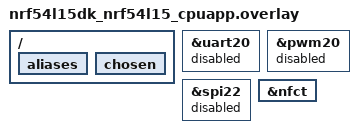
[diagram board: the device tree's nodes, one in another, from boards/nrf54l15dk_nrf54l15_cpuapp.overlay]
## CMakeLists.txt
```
#
# Copyright (c) 2018 Nordic Semiconductor
#
# SPDX-License-Identifier: LicenseRef-Nordic-5-Clause
#

cmake_minimum_required(VERSION 3.20.0)

find_package(Zephyr REQUIRED HINTS $ENV{ZEPHYR_BASE})
project(writable_ndef_msg)

FILE(GLOB app_sources src/*.c)

# NORDIC SDK APP START
target_sources(app  PRIVATE ${app_sources})
# NORDIC SDK APP END
```

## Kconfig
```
#
# Copyright (c) 2025 Nordic Semiconductor
#
# SPDX-License-Identifier: LicenseRef-Nordic-5-Clause
#

source "Kconfig.zephyr"

config ZMS
	select CRC
	default y if (SOC_FLASH_NRF_RRAM || SOC_FLASH_NRF_MRAM)

config NVS
	default y if !(SOC_FLASH_NRF_RRAM || SOC_FLASH_NRF_MRAM)

menu "Nordic UART BLE GATT service sample"

config BT_NUS_THREAD_STACK_SIZE
	int "Thread stack size"
	default 1024
	help
	  Stack size used for the BLE write thread

config BT_NUS_UART_BUFFER_SIZE
	int "UART payload buffer element size"
	default 40
	help
	  Size of the payload buffer in each RX and TX FIFO element

config BT_NUS_SECURITY_ENABLED
	bool "Security"
	default y
	select BT_SMP
	help
	  Enable Bluetooth LE security for the UART service

config BT_NUS_UART_RX_WAIT_TIME
	int "Timeout for UART RX complete event"
	default 50000
	help
	  Wait for RX complete event time in microseconds

config SETTINGS
	default y

endmenu
```

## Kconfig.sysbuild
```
#
# Copyright (c) 2025 Nordic Semiconductor ASA
#
# SPDX-License-Identifier: LicenseRef-Nordic-5-Clause
#

config PARTITION_MANAGER
	default n if !BOARD_IS_NON_SECURE

config NRF_DEFAULT_IPC_RADIO
	default y

config NETCORE_IPC_RADIO_BT_HCI_IPC
	default y

source "share/sysbuild/Kconfig"
```

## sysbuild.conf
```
#
# Copyright (c) 2026 Nordic Semiconductor
#
# SPDX-License-Identifier: LicenseRef-Nordic-5-Clause
#

# BLE requires the network core on multi-core SoCs (nRF5340, nRF54H20).
# For single-core SoCs (nRF52840, nRF52) this has no effect.
```

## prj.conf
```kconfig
#
# Copyright (c) 2019 Nordic Semiconductor ASA
#
# SPDX-License-Identifier: LicenseRef-Nordic-5-Clause
#
CONFIG_NCS_SAMPLES_DEFAULTS=y

# NFC
CONFIG_NFC_T4T_NRFXLIB=y

CONFIG_NFC_NDEF=y
CONFIG_NFC_NDEF_MSG=y
CONFIG_NFC_NDEF_RECORD=y
CONFIG_NFC_NDEF_URI_REC=y
CONFIG_NFC_NDEF_URI_MSG=y

CONFIG_MPU_ALLOW_FLASH_WRITE=y
CONFIG_FLASH=y
CONFIG_FLASH_PAGE_LAYOUT=y
CONFIG_FLASH_MAP=y

# DK buttons and LEDs
CONFIG_DK_LIBRARY=y

CONFIG_SERIAL=y

CONFIG_GPIO=y
CONFIG_CONSOLE=y
CONFIG_UART_CONSOLE=y

# Shell CLI
CONFIG_SHELL=y
CONFIG_SHELL_BACKEND_SERIAL=y
CONFIG_SHELL_STACK_SIZE=2048

CONFIG_HEAP_MEM_POOL_SIZE=2048

# Bluetooth
CONFIG_BT=y
CONFIG_BT_PERIPHERAL=y
CONFIG_BT_DEVICE_NAME="RL_TN100"
CONFIG_BT_MAX_CONN=1
CONFIG_BT_MAX_PAIRED=1

# BT buffer pool — OTA 每包 492 字节，ATT payload 495，MTU 498
CONFIG_BT_L2CAP_TX_MTU=498
CONFIG_BT_BUF_ACL_TX_SIZE=502
CONFIG_BT_BUF_ACL_TX_COUNT=6
CONFIG_BT_BUF_ACL_RX_SIZE=502
CONFIG_BT_BUF_ACL_RX_COUNT_EXTRA=4
CONFIG_BT_BUF_EVT_RX_COUNT=12

# NUS service
CONFIG_BT_NUS=y

# Bonding
CONFIG_BT_SETTINGS=y

CONFIG_SYSTEM_WORKQUEUE_STACK_SIZE=2048

# Logger
CONFIG_LOG=y
CONFIG_LOG_MODE_MINIMAL=n
CONFIG_USE_SEGGER_RTT=n
CONFIG_LOG_BACKEND_RTT=n
CONFIG_LOG_BACKEND_UART=y
CONFIG_LOG_PRINTK=y

# Entropy for random nonce
CONFIG_ENTROPY_GENERATOR=y

CONFIG_ASSERT=y
```

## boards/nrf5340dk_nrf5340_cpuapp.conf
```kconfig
#
# Copyright (c) 2024 Nordic Semiconductor ASA
#
# SPDX-License-Identifier: LicenseRef-Nordic-5-Clause
#

# nRF5340 app core: use host crypto PRNG instead of
# getting entropy from the network core via HCI.
CONFIG_BT_HOST_CRYPTO_PRNG=y
CONFIG_ENTROPY_BT_HCI=n
```

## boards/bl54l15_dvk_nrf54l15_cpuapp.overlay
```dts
/*
 * DK/App integration overlay.
 *
 * Keep the nRF54L15 DK defaults for UART console, shell, LEDs and buttons,
 * and only enable the NFCT peripheral required by the writable NDEF sample.
 * The PCB-A pin-protection overlay belongs on the dedicated test branch.
 */

&nfct {
	status = "okay";
};
```

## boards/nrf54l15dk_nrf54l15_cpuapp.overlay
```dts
/*
 * Copyright (c) 2024-2026
 *
 * SPDX-License-Identifier: LicenseRef-Nordic-5-Clause
 *
 * PCB-A nRF54L15 最小 overlay — NFC + BLE 联调阶段
 *
 * 仅启用 NFC 和 BLE 两个可调试功能。
 * 其余外设引脚已按 docs/pcb_a_io_map.md 分配，
 * 待各外设驱动就绪后逐步加入此 overlay。
 */

/* ── 清除 DK 默认节点与别名（释放 GPIO） ── */
/ {
	/delete-node/ leds;
	/delete-node/ buttons;
	/delete-node/ pwmleds;

	aliases {
		/delete-property/ led0;
		/delete-property/ led1;
		/delete-property/ led2;
		/delete-property/ led3;
		/delete-property/ pwm-led0;
		/delete-property/ sw0;
		/delete-property/ sw1;
		/delete-property/ sw2;
		/delete-property/ sw3;
		/delete-property/ mcuboot-button0;
		/delete-property/ mcuboot-led0;
	};

	/* 清理 chosen 中引用已禁用 uart20 的属性，避免构建警告 */
	chosen {
		/delete-property/ zephyr,console;
		/delete-property/ zephyr,shell-uart;
		/delete-property/ zephyr,uart-mcumgr;
		/delete-property/ zephyr,bt-mon-uart;
		/delete-property/ zephyr,bt-c2h-uart;
	};
};

/* ── 释放 uart20 占用的 P1.04~P1.07 ── */
/* PCB-A: P1.04=NTC_ADC, P1.05=VBAT_ADC, P1.06=US_RX, P1.07=US_TX */
&uart20 {
	/delete-property/ pinctrl-0;
	/delete-property/ pinctrl-1;
	/delete-property/ pinctrl-names;
	status = "disabled";
};

/* ── 释放 pwm20 占用的 P1.10 ── */
/* PCB-A: P1.10=CC_I2C_SDA (ATECC608C) */
&pwm20 {
	/delete-property/ pinctrl-0;
	/delete-property/ pinctrl-1;
	/delete-property/ pinctrl-names;
	status = "disabled";
};

/* ── 释放 spi22 占用的 P1.06/P1.07/P1.11 ── */
/* PCB-A: P1.06=US_RX, P1.07=US_TX, P1.11=CC_I2C_SCL */
&spi22 {
	/delete-property/ pinctrl-0;
	/delete-property/ pinctrl-1;
	/delete-property/ pinctrl-names;
	/delete-property/ cs-gpios;
	status = "disabled";
};

/* ── GRTC — 无需禁用 ──
 * DK 默认 &grtc pinctrl (grtc_default/grtc_sleep) 使用 /omit-if-no-ref/ 编译指令，
 * 且 &grtc 节点本身未引用这两个 pinctrl 配置（见 rf54l_05_10_15_cpuapp_common.dtsi:53-58）。
 * 因此 GRTC CLKOUT_FAST(P1.08) / CLKOUT_32K(P0.04) 引脚不会被占用，
 * PCB-A 的 LED_PWM(P1.08) / ACC_I2C_SCL(P0.04) 无冲突风险。
 * GRTC 作为内部定时器保持使能，不影响 GPIO。
 */

/* ── NFC 使能（P1.02/P1.03 固定功能，与 PCB-A 一致） ── */
&nfct {
	status = "okay";
};

/* ── Flash SPIM00 — DK 默认与 PCB-A 一致，无需覆盖 ── */
/* P2.01=SCK, P2.02=MOSI, P2.04=MISO, P2.05=CS → W25Q32JVSSIQ */

/* ═══════════════════════════════════════════════════════════════
 * 以下为 PCB-A 外设预留引脚说明（暂不启用，只做文档记录）
 * 参见 docs/pcb_a_io_map.md 完整分配表
 * ═══════════════════════════════════════════════════════════════
 *
 * ── 硬件 I2C ──
 * TWIM30 (BMA510) : P0.04 SCL / P0.03 SDA  (常开低功耗域)
 * TWIM20 (TOF)    : P1.12 SCL / P1.13 SDA
 * TWIM22 (ATECC)  : P1.11 SCL / P1.10 SDA
 *
 * ── 硬件 UART ──
 * UART21 (LPWA)   : P2.08 TXD / P2.07 RXD  (P2.07 与 SWO 复用)
 *
 * ── 软件 UART (GPIO bit-bang) ──
 * 超声波           : P1.07 TX / P1.06 RX
 * GNSS (预留)      : P2.09 TX / P2.10 RX     (P2 无 GPIOTE)
 *
 * ── ADC ──
 * SAADC AIN0 (NTC) : P1.04
 * SAADC AIN1 (VBAT): P1.05
 *
 * ── GPIO ──
 * P0.00 NTC_INT    (输入, wake)
 * P0.01 REST_KEY   (输入, wake, 低有效)
 * P0.02 ACC_INT    (输入, wake, BMA510)
 * P1.08 LED_PWM    (输出, WS2812B)
 * P1.09 MK_EN      (输出, 电源控制, 默认关断)
 * P1.14 TOF_INT    (输入, wake)
 * P2.00 LPWA_POWER (输出, PWRKEY 时序)
 * P2.03 LPWA_EN    (输出, 电源使能)
 * P2.06 LPWA_PSM   (输出, PSM 控制)
 *
 * ── 固定功能（无需 overlay） ──
 * P1.00 OSC32IN / P1.01 OSC32OUT (32.768kHz 晶振)
 * P1.02 NFC1  / P1.03 NFC2       (NFC 天线)
 * ANT (BLE 射频)
 */
```

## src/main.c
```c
/*
 * Copyright (c) 2018 Nordic Semiconductor ASA
 *
 * SPDX-License-Identifier: LicenseRef-Nordic-5-Clause
 */

/** @file
 *
 * @defgroup nfc_writable_ndef_msg_example_main main.c
 * @{
 * @ingroup nfc_writable_ndef_msg_example
 * @brief The application main file of NFC writable NDEF message example.
 *
 */

#include <zephyr/kernel.h>
#include <zephyr/sys/reboot.h>
#include <stdbool.h>
#include <nfc_t4t_lib.h>

#include <nfc/ndef/msg.h>
#include <nfc/t4t/ndef_file.h>

#if defined(CONFIG_DK_LIBRARY)
#include <dk_buttons_and_leds.h>
#endif

#include "ndef_file_m.h"
#include "app_config.h"
#include "app_fields.h"
#include "app_auth.h"
#include "ble_uart.h"


#if defined(CONFIG_DK_LIBRARY)
#define NFC_FIELD_LED		DK_LED1
#define NFC_WRITE_LED		DK_LED2
#define NFC_READ_LED		DK_LED4

#define NDEF_RESTORE_BTN_MSK	DK_BTN1_MSK
#endif

static uint8_t ndef_msg_buf[CONFIG_NDEF_FILE_SIZE]; /**< Buffer for NDEF file. */

enum {
	FLASH_WRITE_FINISHED,
	FLASH_BUF_PREP_STARTED,
	FLASH_BUF_PREP_FINISHED,
	FLASH_WRITE_STARTED,
};
static atomic_t op_flags;
static uint8_t flash_buf[CONFIG_NDEF_FILE_SIZE]; /**< Buffer for flash update. */
static uint8_t flash_buf_len; /**< Length of the flash buffer. */

static K_SEM_DEFINE(nfc_write_sem, 0, 1);

static void flash_buffer_prepare(size_t data_length)
{
	if (atomic_cas(&op_flags, FLASH_WRITE_FINISHED,
			FLASH_BUF_PREP_STARTED)) {
		flash_buf_len = data_length + NFC_NDEF_FILE_NLEN_FIELD_SIZE;
		memcpy(flash_buf, ndef_msg_buf, sizeof(flash_buf));

		atomic_set(&op_flags, FLASH_BUF_PREP_FINISHED);
		k_sem_give(&nfc_write_sem);
	} else {
		printk("Flash update pending. Discarding new data...\n");
	}

}

/**
 * @brief Callback function for handling NFC events.
 */
static void nfc_callback(void *context,
			 nfc_t4t_event_t event,
			 const uint8_t *data,
			 size_t data_length,
			 uint32_t flags)
{
	ARG_UNUSED(context);
	ARG_UNUSED(flags);

	switch (event) {
	case NFC_T4T_EVENT_FIELD_ON:
#if defined(CONFIG_DK_LIBRARY)
		dk_set_led_on(NFC_FIELD_LED);
#endif
		break;

	case NFC_T4T_EVENT_FIELD_OFF:
#if defined(CONFIG_DK_LIBRARY)
		dk_set_led_off(NFC_FIELD_LED);
		dk_set_led_off(NFC_WRITE_LED);
		dk_set_led_off(NFC_READ_LED);
#endif
		break;

	case NFC_T4T_EVENT_NDEF_READ:
#if defined(CONFIG_DK_LIBRARY)
		dk_set_led_on(NFC_READ_LED);
#endif
		break;

	case NFC_T4T_EVENT_NDEF_UPDATED:
		if (data_length > 0) {
#if defined(CONFIG_DK_LIBRARY)
			dk_set_led_on(NFC_WRITE_LED);
#endif

			if (!app_config_handle_ndef(ndef_msg_buf, sizeof(ndef_msg_buf))) {
				flash_buffer_prepare(data_length);
			}
		}
		break;

	default:
		break;
	}
}

static int board_init(void)
{
#if defined(CONFIG_DK_LIBRARY)
	int err = dk_leds_init();
	if (err) {
		printk("Cannot init LEDs (err: %d)\n", err);
		return err;
	}
#endif

	return 0;
}

/**
 * @brief   Function for application main entry.
 */
int main(void)
{
	/* Configure LED-pins as outputs. */
	if (board_init() < 0) {
		printk("Cannot initialize board!\n");
		goto fail;
	}
	/* Initialize storage. */
	if (ndef_file_setup() < 0) {
		printk("Cannot setup NDEF file!\n");
		goto fail;
	}
	/* Load NDEF message from the flash file. */
	if (ndef_file_load(ndef_msg_buf, sizeof(ndef_msg_buf)) < 0) {
		printk("Cannot load NDEF file!\n");
		goto fail;
	}

#if defined(CONFIG_DK_LIBRARY)
	/* Restore default NDEF message if button is pressed. */
	uint32_t button_state;

	dk_read_buttons(&button_state, NULL);
	if (button_state & NDEF_RESTORE_BTN_MSK) {
		if (ndef_restore_default(ndef_msg_buf,
					 sizeof(ndef_msg_buf)) < 0) {
			printk("Cannot flash NDEF message!\n");
			goto fail;
		}
		printk("Default NDEF message restored!\n");
	}
#endif
	/* Set up NFC */
	int err = nfc_t4t_setup(nfc_callback, NULL);

	if (err < 0) {
		printk("Cannot setup t4t library!\n");
		goto fail;
	}
	/* Run Read-Write mode for Type 4 Tag platform */
	if (nfc_t4t_ndef_rwpayload_set(ndef_msg_buf,
				       sizeof(ndef_msg_buf)) < 0) {
		printk("Cannot set payload!\n");
		goto fail;
	}
	/* Start sensing NFC field */
	if (nfc_t4t_emulation_start() < 0) {
		printk("Cannot start emulation!\n");
		goto fail;
	}
	printk("Starting NFC Writable NDEF Message sample\n");

	/* Initialize authentication module */
	app_auth_init();
	/* Initialize field registry (V2.0 protocol) */
	app_fields_init();

	/* Initialize BLE UART service */
	err = ble_uart_init();
	if (err) {
		printk("Cannot initialize BLE UART (err: %d)\n", err);
		goto fail;
	}

	while (true) {
		k_sem_take(&nfc_write_sem, K_FOREVER);
		if (atomic_cas(&op_flags, FLASH_BUF_PREP_FINISHED,
				FLASH_WRITE_STARTED)) {
			if (ndef_file_update(flash_buf, flash_buf_len) < 0) {
				printk("Cannot flash NDEF message!\n");
			} else {
				printk("NDEF message successfully flashed.\n");
			}

			atomic_set(&op_flags, FLASH_WRITE_FINISHED);
		}
	}

fail:
	#if CONFIG_REBOOT
		sys_reboot(SYS_REBOOT_COLD);
	#endif /* CONFIG_REBOOT */
		return -EIO;
}
/** @} */
```

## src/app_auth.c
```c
/*
 * Copyright (c) 2024
 *
 * SPDX-License-Identifier: LicenseRef-Nordic-5-Clause
 */

/**
 * @file app_auth.c
 * @brief CMD 0x03 认证与密码管理模块。
 *
 * 测试阶段默认密码: 123456
 * password_hash = SHA256(password + device_sn + salt)
 * salt = "RL_RANGE_AUTH_V1"
 * token = HMAC_SHA256(password_hash, nonce + device_sn)
 *
 * SHA256 与 HMAC-SHA256 为自包含实现，不依赖外部密码库。
 *
 * 【密码持久化策略】
 * 本测试工程暂不将 password_hash 写入 Flash，修改密码仅保存在 RAM 中。
 * 设备重启后 password_hash 恢复为默认密码 "123456" 的计算值。
 * 如需完整测试修改密码，应使用 Zephyr settings 或 Flash KV 持久化
 * password_hash，在 app_auth_init() 中先从持久化存储加载，不存在时
 * 再 fallback 到默认密码。
 */

#include "app_auth.h"
#include "app_config.h"

#include <zephyr/kernel.h>
#include <zephyr/sys/printk.h>
#include <zephyr/random/random.h>

#include <string.h>

/* ── 设备身份 ── */

static const char g_sn[]   = "123456";      /* 与 app_config.c 保持一致 */
static const char g_salt[] = "RL_RANGE_AUTH_V1";

/* ── 默认测试密码 ── */

#define DEFAULT_PASSWORD "123456"

/* ── 密码哈希（32 字节 SHA256，设备端永不保留明文） ── */

static uint8_t g_password_hash[32];

/* ── BLE / NFC 独立 nonce 状态，避免两个通道互相覆盖 ── */

static uint8_t g_nonce_ble[8];
static bool    g_nonce_ble_valid;
static uint8_t g_nonce_nfc[8];
static bool    g_nonce_nfc_valid;

/* ── 按通道取 nonce 指针 ── */

static uint8_t *channel_nonce(const char *channel)
{
	return (channel[0] == 'B') ? g_nonce_ble : g_nonce_nfc;
}

static bool *channel_nonce_valid(const char *channel)
{
	return (channel[0] == 'B') ? &g_nonce_ble_valid : &g_nonce_nfc_valid;
}

/* ── 会话解锁状态 ── */

static bool     g_ble_unlocked;
static int64_t  g_nfc_auth_until_ms;  /* k_uptime_get() + 5*60*1000，0 = 锁定 */
#define NFC_AUTH_WINDOW_MS  (5 * 60 * 1000)

/* ═══════════════════════════════════════════════════════════════════════
 * 自包含 SHA256 实现 (FIPS 180-4)
 * ═══════════════════════════════════════════════════════════════════════ */

#define SHA256_BLOCK_SIZE 64
#define SHA256_HASH_SIZE  32

struct sha256_ctx {
	uint32_t state[8];
	uint64_t count;
	uint8_t  buf[SHA256_BLOCK_SIZE];
};

static const uint32_t sha256_k[64] = {
	0x428a2f98, 0x71374491, 0xb5c0fbcf, 0xe9b5dba5,
	0x3956c25b, 0x59f111f1, 0x923f82a4, 0xab1c5ed5,
	0xd807aa98, 0x12835b01, 0x243185be, 0x550c7dc3,
	0x72be5d74, 0x80deb1fe, 0x9bdc06a7, 0xc19bf174,
	0xe49b69c1, 0xefbe4786, 0x0fc19dc6, 0x240ca1cc,
	0x2de92c6f, 0x4a7484aa, 0x5cb0a9dc, 0x76f988da,
	0x983e5152, 0xa831c66d, 0xb00327c8, 0xbf597fc7,
	0xc6e00bf3, 0xd5a79147, 0x06ca6351, 0x14292967,
	0x27b70a85, 0x2e1b2138, 0x4d2c6dfc, 0x53380d13,
	0x650a7354, 0x766a0abb, 0x81c2c92e, 0x92722c85,
	0xa2bfe8a1, 0xa81a664b, 0xc24b8b70, 0xc76c51a3,
	0xd192e819, 0xd6990624, 0xf40e3585, 0x106aa070,
	0x19a4c116, 0x1e376c08, 0x2748774c, 0x34b0bcb5,
	0x391c0cb3, 0x4ed8aa4a, 0x5b9cca4f, 0x682e6ff3,
	0x748f82ee, 0x78a5636f, 0x84c87814, 0x8cc70208,
	0x90befffa, 0xa4506ceb, 0xbef9a3f7, 0xc67178f2
};

static inline uint32_t sha256_rotr(uint32_t x, uint32_t n)
{
	return (x >> n) | (x << (32 - n));
}

static inline uint32_t sha256_ch(uint32_t x, uint32_t y, uint32_t z)
{
	return (x & y) ^ (~x & z);
}

static inline uint32_t sha256_maj(uint32_t x, uint32_t y, uint32_t z)
{
	return (x & y) ^ (x & z) ^ (y & z);
}

static inline uint32_t sha256_bsig0(uint32_t x)
{
	return sha256_rotr(x, 2) ^ sha256_rotr(x, 13) ^ sha256_rotr(x, 22);
}

static inline uint32_t sha256_bsig1(uint32_t x)
{
	return sha256_rotr(x, 6) ^ sha256_rotr(x, 11) ^ sha256_rotr(x, 25);
}

static inline uint32_t sha256_ssig0(uint32_t x)
{
	return sha256_rotr(x, 7) ^ sha256_rotr(x, 18) ^ (x >> 3);
}

static inline uint32_t sha256_ssig1(uint32_t x)
{
	return sha256_rotr(x, 17) ^ sha256_rotr(x, 19) ^ (x >> 10);
}

static inline uint32_t sha256_get32be(const uint8_t *p)
{
	return ((uint32_t)p[0] << 24) | ((uint32_t)p[1] << 16) |
	       ((uint32_t)p[2] << 8)  |  (uint32_t)p[3];
}

static inline void sha256_put32be(uint8_t *p, uint32_t v)
{
	p[0] = (uint8_t)(v >> 24);
	p[1] = (uint8_t)(v >> 16);
	p[2] = (uint8_t)(v >> 8);
	p[3] = (uint8_t)(v);
}

static void sha256_transform(uint32_t *state, const uint8_t *block)
{
	uint32_t w[64];
	uint32_t a, b, c, d, e, f, g, h;
	uint32_t t1, t2;

	for (int i = 0; i < 16; i++) {
		w[i] = sha256_get32be(&block[i * 4]);
	}
	for (int i = 16; i < 64; i++) {
		w[i] = sha256_ssig1(w[i - 2]) + w[i - 7] +
		       sha256_ssig0(w[i - 15]) + w[i - 16];
	}

	a = state[0]; b = state[1]; c = state[2]; d = state[3];
	e = state[4]; f = state[5]; g = state[6]; h = state[7];

	for (int i = 0; i < 64; i++) {
		t1 = h + sha256_bsig1(e) + sha256_ch(e, f, g) + sha256_k[i] + w[i];
		t2 = sha256_bsig0(a) + sha256_maj(a, b, c);
		h = g; g = f; f = e; e = d + t1;
		d = c; c = b; b = a; a = t1 + t2;
	}

	state[0] += a; state[1] += b; state[2] += c; state[3] += d;
	state[4] += e; state[5] += f; state[6] += g; state[7] += h;
}

static void sha256_init(struct sha256_ctx *ctx)
{
	ctx->state[0] = 0x6a09e667;
	ctx->state[1] = 0xbb67ae85;
	ctx->state[2] = 0x3c6ef372;
	ctx->state[3] = 0xa54ff53a;
	ctx->state[4] = 0x510e527f;
	ctx->state[5] = 0x9b05688c;
	ctx->state[6] = 0x1f83d9ab;
	ctx->state[7] = 0x5be0cd19;
	ctx->count = 0;
}

static void sha256_update(struct sha256_ctx *ctx,
			  const uint8_t *data, size_t len)
{
	size_t idx = (size_t)(ctx->count & 0x3F); /* ctx->count % 64 */
	ctx->count += (uint64_t)len;

	while (len > 0) {
		size_t fill = SHA256_BLOCK_SIZE - idx;
		if (fill > len) {
			fill = len;
		}
		memcpy(ctx->buf + idx, data, fill);
		idx += fill;
		data += fill;
		len -= fill;

		if (idx == SHA256_BLOCK_SIZE) {
			sha256_transform(ctx->state, ctx->buf);
			idx = 0;
		}
	}
}

static void sha256_finish(struct sha256_ctx *ctx, uint8_t *hash)
{
	uint64_t bits = ctx->count * 8;
	size_t idx = (size_t)(ctx->count & 0x3F);

	/* padding: 0x80, then zeros, then 8-byte big-endian bit count */
	ctx->buf[idx++] = 0x80;
	if (idx > 56) {
		memset(ctx->buf + idx, 0, SHA256_BLOCK_SIZE - idx);
		sha256_transform(ctx->state, ctx->buf);
		idx = 0;
	}
	memset(ctx->buf + idx, 0, 56 - idx);
	sha256_put32be(ctx->buf + 56, (uint32_t)(bits >> 32));
	sha256_put32be(ctx->buf + 60, (uint32_t)(bits));
	sha256_transform(ctx->state, ctx->buf);

	for (int i = 0; i < 8; i++) {
		sha256_put32be(hash + i * 4, ctx->state[i]);
	}
}

/* ═══════════════════════════════════════════════════════════════════════
 * 自包含 HMAC-SHA256 实现 (RFC 2104)
 * ═══════════════════════════════════════════════════════════════════════ */

static void hmac_sha256(const uint8_t *key, size_t key_len,
			const uint8_t *msg, size_t msg_len,
			uint8_t *hmac_out)
{
	uint8_t key_pad[SHA256_BLOCK_SIZE];
	struct sha256_ctx ctx;
	uint8_t inner_hash[SHA256_HASH_SIZE];

	/* 如果 key 长于 block size，先 hash */
	if (key_len > SHA256_BLOCK_SIZE) {
		sha256_init(&ctx);
		sha256_update(&ctx, key, key_len);
		sha256_finish(&ctx, key_pad);
		memset(key_pad + SHA256_HASH_SIZE, 0,
		       SHA256_BLOCK_SIZE - SHA256_HASH_SIZE);
	} else {
		memcpy(key_pad, key, key_len);
		if (key_len < SHA256_BLOCK_SIZE) {
			memset(key_pad + key_len, 0,
			       SHA256_BLOCK_SIZE - key_len);
		}
	}

	/* inner: H((key_pad ^ ipad) || msg) */
	uint8_t inner_key[SHA256_BLOCK_SIZE];
	for (int i = 0; i < SHA256_BLOCK_SIZE; i++) {
		inner_key[i] = key_pad[i] ^ 0x36;
	}
	sha256_init(&ctx);
	sha256_update(&ctx, inner_key, SHA256_BLOCK_SIZE);
	sha256_update(&ctx, msg, msg_len);
	sha256_finish(&ctx, inner_hash);

	/* outer: H((key_pad ^ opad) || inner_hash) */
	uint8_t outer_key[SHA256_BLOCK_SIZE];
	for (int i = 0; i < SHA256_BLOCK_SIZE; i++) {
		outer_key[i] = key_pad[i] ^ 0x5C;
	}
	sha256_init(&ctx);
	sha256_update(&ctx, outer_key, SHA256_BLOCK_SIZE);
	sha256_update(&ctx, inner_hash, SHA256_HASH_SIZE);
	sha256_finish(&ctx, hmac_out);
}

/* ═══════════════════════════════════════════════════════════════════════
 * 密码哈希辅助
 * ═══════════════════════════════════════════════════════════════════════ */

/**
 * @brief 计算密码哈希。
 *
 *   password_hash = SHA256(password || device_sn || salt)
 */
static void compute_password_hash(const char *password,
				  const char *sn,
				  const char *salt,
				  uint8_t *hash_out)
{
	struct sha256_ctx ctx;

	sha256_init(&ctx);
	sha256_update(&ctx, (const uint8_t *)password, strlen(password));
	sha256_update(&ctx, (const uint8_t *)sn,       strlen(sn));
	sha256_update(&ctx, (const uint8_t *)salt,      strlen(salt));
	sha256_finish(&ctx, hash_out);
}

/* ═══════════════════════════════════════════════════════════════════════
 * 会话管理
 * ═══════════════════════════════════════════════════════════════════════ */

static void channel_lock(const char *channel)
{
	if (channel[0] == 'B') {
		g_ble_unlocked = false;
		*channel_nonce_valid(channel) = false;
		printk("[AUTH] BLE locked\n");
	} else {
		g_nfc_auth_until_ms = 0;
		*channel_nonce_valid(channel) = false;
		printk("[AUTH] NFC locked\n");
	}
}

static void channel_unlock(const char *channel)
{
	if (channel[0] == 'B') {
		g_ble_unlocked = true;
		printk("[AUTH] BLE unlocked (this connection)\n");
	} else {
		g_nfc_auth_until_ms = k_uptime_get() + NFC_AUTH_WINDOW_MS;
		printk("[AUTH] NFC unlocked for %u s\n",
		       (unsigned)(NFC_AUTH_WINDOW_MS / 1000));
	}
}

/* ═══════════════════════════════════════════════════════════════════════
 * 公共 API
 * ═══════════════════════════════════════════════════════════════════════ */

void app_auth_init(void)
{
	compute_password_hash(DEFAULT_PASSWORD, g_sn, g_salt, g_password_hash);
	printk("[AUTH] init OK (default password, RAM-only, lost on reboot)\n");
}

void app_auth_reset_password(void)
{
	compute_password_hash(DEFAULT_PASSWORD, g_sn, g_salt, g_password_hash);
	printk("[AUTH] password reset to default\n");
}

uint16_t app_auth_handle_cmd(const uint8_t *data, uint16_t len,
			     uint8_t *resp, const char *channel)
{
	if (len < 2 || data[0] != APP_CONFIG_CMD_AUTH) {
		return 0;
	}

	uint8_t subcmd = data[1];
	uint8_t *nonce = channel_nonce(channel);
	bool *nonce_valid = channel_nonce_valid(channel);

	switch (subcmd) {

	/* ── 0x01: 请求 nonce ── */
	case APP_CONFIG_AUTH_SUBCMD_NONCE: {
		sys_rand_get(nonce, 8);
		*nonce_valid = true;

		resp[0] = APP_CONFIG_CMD_AUTH;
		resp[1] = APP_CONFIG_STATUS_OK;
		resp[2] = APP_CONFIG_AUTH_SUBCMD_NONCE;
		memcpy(&resp[3], nonce, 8);

		printk("[AUTH] %s nonce issued\n", channel);
		return 11;
	}

	/* ── 0x02: 提交认证 token ── */
	case APP_CONFIG_AUTH_SUBCMD_TOKEN: {
		if (len < 34) {
			resp[0] = APP_CONFIG_CMD_AUTH;
			resp[1] = APP_CONFIG_STATUS_PARAM_LEN;
			resp[2] = APP_CONFIG_AUTH_SUBCMD_TOKEN;
			return 3;
		}

		if (!*nonce_valid) {
			resp[0] = APP_CONFIG_CMD_AUTH;
			resp[1] = APP_CONFIG_STATUS_AUTH_STATE;
			resp[2] = APP_CONFIG_AUTH_SUBCMD_TOKEN;
			resp[3] = APP_CONFIG_AUTH_STATE_LOCKED;
			printk("[AUTH] %s token without nonce\n", channel);
			return 4;
		}

		/* 构造 HMAC 消息: nonce(8) || sn */
		uint8_t hmac_msg[256];
		size_t sn_len = strlen(g_sn);
		memcpy(hmac_msg, nonce, 8);
		memcpy(hmac_msg + 8, g_sn, sn_len);

		/* 计算期望 token */
		uint8_t expected[32];
		hmac_sha256(g_password_hash, 32,
			    hmac_msg, 8 + sn_len,
			    expected);

		/* 真正常量时间比较：始终遍历全部 32 字节，无提前退出 */
		const uint8_t *received = &data[2];
		uint8_t diff = 0;
		for (int i = 0; i < 32; i++) {
			diff |= (expected[i] ^ received[i]);
		}
		bool match = (diff == 0);

		/* 无论成功与否都消费 nonce（一次性使用） */
		*nonce_valid = false;

		resp[0] = APP_CONFIG_CMD_AUTH;

		if (match) {
			channel_unlock(channel);
			resp[1] = APP_CONFIG_STATUS_OK;
			resp[2] = APP_CONFIG_AUTH_SUBCMD_TOKEN;
			resp[3] = APP_CONFIG_AUTH_STATE_UNLOCKED;
			printk("[AUTH] %s token OK\n", channel);
		} else {
			channel_lock(channel);
			resp[1] = APP_CONFIG_STATUS_AUTH_FAILED;
			resp[2] = APP_CONFIG_AUTH_SUBCMD_TOKEN;
			resp[3] = APP_CONFIG_AUTH_STATE_LOCKED;
			printk("[AUTH] %s token mismatch\n", channel);
		}
		return 4;
	}

	/* ── 0x03: 修改密码 ── */
	case APP_CONFIG_AUTH_SUBCMD_CHANGE_PWD: {
		uint8_t st = app_auth_check_write(channel);
		if (st != APP_CONFIG_STATUS_OK) {
			resp[0] = APP_CONFIG_CMD_AUTH;
			resp[1] = st;
			resp[2] = APP_CONFIG_AUTH_SUBCMD_CHANGE_PWD;
			return 3;
		}

		if (len < 34) {
			resp[0] = APP_CONFIG_CMD_AUTH;
			resp[1] = APP_CONFIG_STATUS_PARAM_LEN;
			resp[2] = APP_CONFIG_AUTH_SUBCMD_CHANGE_PWD;
			return 3;
		}

		/* 保存新密码 hash（32 字节，仅 RAM，重启丢失恢复默认） */
		memcpy(g_password_hash, &data[2], 32);

		resp[0] = APP_CONFIG_CMD_AUTH;
		resp[1] = APP_CONFIG_STATUS_OK;
		resp[2] = APP_CONFIG_AUTH_SUBCMD_CHANGE_PWD;

		printk("[AUTH] %s password changed (RAM-only, lost on reboot)\n",
		       channel);
		return 3;
	}

	/* ── 0x04: 主动锁定 ── */
	case APP_CONFIG_AUTH_SUBCMD_LOCK: {
		channel_lock(channel);

		resp[0] = APP_CONFIG_CMD_AUTH;
		resp[1] = APP_CONFIG_STATUS_OK;
		resp[2] = APP_CONFIG_AUTH_SUBCMD_LOCK;
		return 3;
	}

	default:
		resp[0] = APP_CONFIG_CMD_AUTH;
		resp[1] = APP_CONFIG_STATUS_UNSUPPORTED;
		resp[2] = subcmd;
		return 3;
	}
}

uint8_t app_auth_check_write(const char *channel)
{
	if (channel[0] == 'B') {
		if (g_ble_unlocked) {
			return APP_CONFIG_STATUS_OK;
		}
		return APP_CONFIG_STATUS_AUTH_REQUIRED;
	}

	/* NFC: 惰性检查时效 */
	if (g_nfc_auth_until_ms > 0) {
		if ((int64_t)k_uptime_get() <= g_nfc_auth_until_ms) {
			return APP_CONFIG_STATUS_OK;
		}
		g_nfc_auth_until_ms = 0;
		return APP_CONFIG_STATUS_AUTH_EXPIRED;
	}
	return APP_CONFIG_STATUS_AUTH_REQUIRED;
}

void app_auth_ble_disconnect(void)
{
	g_ble_unlocked = false;
	g_nonce_ble_valid = false;
	printk("[AUTH] BLE disconnected, lock & nonce cleared\n");
}
```

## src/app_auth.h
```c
/*
 * Copyright (c) 2024
 *
 * SPDX-License-Identifier: LicenseRef-Nordic-5-Clause
 */

#ifndef APP_AUTH_H__
#define APP_AUTH_H__

#include <stdint.h>
#include <stdbool.h>
#include <stddef.h>

#ifdef __cplusplus
extern "C" {
#endif

/**
 * @brief 初始化认证模块。
 *        计算默认密码 password_hash = SHA256("123456" + SN + SALT)。
 *        启动后 BLE 和 NFC 均为锁定状态。
 *
 *        【密码持久化】本测试工程暂不将 password_hash 写入 Flash，
 *        修改密码仅保存在 RAM 中，设备重启后恢复为默认密码 "123456"。
 *        如需完整测试修改密码，应在此函数中先从 Zephyr settings 或
 *        Flash KV 加载已保存的 password_hash，不存在时再 fallback 到默认密码。
 */
void app_auth_init(void);

/**
 * @brief 处理 CMD 0x03 认证与密码管理命令。
 *
 * @param data    收到的命令 payload（含 CMD 字节），如 [03, subcmd, args...]
 * @param len     payload 长度
 * @param resp    输出响应缓冲区
 * @param channel 通道名称："BLE" 或 "NFC"
 * @return 响应字节数（写入 resp），0 表示不是 CMD 0x03
 */
uint16_t app_auth_handle_cmd(const uint8_t *data, uint16_t len,
			     uint8_t *resp, const char *channel);

/**
 * @brief 检查当前通道是否已解锁（允许写操作）。
 *
 * @param channel "BLE" 或 "NFC"
 * @return 0x00 已解锁，否则为错误码：
 *         - 0x0A AUTH_FAILED
 *         - 0x0B AUTH_REQUIRED
 *         - 0x0C AUTH_EXPIRED
 */
uint8_t app_auth_check_write(const char *channel);

/** BLE 断开连接时调用，清除 BLE 解锁状态 */
void app_auth_ble_disconnect(void);

/** 恢复出厂时调用，重置密码 hash 为默认值 "123456" */
void app_auth_reset_password(void);

#ifdef __cplusplus
}
#endif

#endif /* APP_AUTH_H__ */
```

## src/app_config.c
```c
/*
 * Copyright (c) 2024
 *
 * SPDX-License-Identifier: LicenseRef-Nordic-5-Clause
 */

#include "app_config.h"
#include "app_fields.h"
#include "app_auth.h"

#include <zephyr/kernel.h>
#include <string.h>
#include <nfc_t4t_lib.h>
#include <nfc/t4t/ndef_file.h>

/* ── 字段数据已迁移至 app_fields.c，此处仅保留传输层逻辑 ── */

/* ── 传感器 setter 函数（转发到字段模块）── */

void app_config_set_battery(uint8_t level)     { app_field_set_battery(level); }
void app_config_set_temperature(int16_t temp)   { app_field_set_temperature(temp); }
void app_config_set_distance(uint16_t dist)     { app_field_set_distance(dist); }
void app_config_set_position(uint8_t pos)       { app_field_set_position(pos); }
void app_config_set_mode(uint8_t mode)          { app_field_set(FIELD_MODE, &mode, 1); }
void app_config_set_update_time(uint16_t interval) {
	uint8_t buf[2];
	buf[0] = (uint8_t)(interval >> 8);
	buf[1] = (uint8_t)(interval);
	app_field_set(FIELD_UPDATE_INTERVAL, buf, 2);
}
void app_config_set_gnss_fix(uint8_t fix)       { app_field_set_gnss_fix(fix); }
void app_config_set_latitude(int32_t lat)       { app_field_set_latitude(lat); }
void app_config_set_longitude(int32_t lng)      { app_field_set_longitude(lng); }
void app_config_set_altitude(int16_t alt)       { app_field_set_altitude(alt); }

/* ── 全局时间戳 ── */

uint32_t app_config_get_unixtime(void)
{
	return app_field_get_unixtime();
}

/* ── 可读名称映射 ── */

static const char *mode_name(uint8_t mode)
{
	switch (mode) {
	case 0x01: return "bin";
	case 0x02: return "trash";
	case 0x03: return "shelf";
	default:   return "unknown";
	}
}

static const char *pos_name(uint8_t pos)
{
	switch (pos) {
	case 0x00: return "normal";
	case 0x01: return "tilt";
	default:   return "unknown";
	}
}

/* ── OTA 状态（调试阶段：数据存 RAM） ── */

struct ota_state {
	bool     active;
	bool     done;
	uint32_t total_size;
	uint16_t next_idx;
	uint32_t bytes_received;
	uint8_t  buf[APP_CONFIG_OTA_BUF_SIZE];
};

static struct ota_state g_ota;

void app_config_ota_get_info(struct app_config_ota_info *info)
{
	info->active           = g_ota.active;
	info->done             = g_ota.done;
	info->total_size       = g_ota.total_size;
	info->packets_received = g_ota.next_idx;
	info->bytes_received   = g_ota.bytes_received;
}

const uint8_t *app_config_ota_get_buf(void)
{
	return g_ota.buf;
}

/* ── NDEF记录标志 ── */

#define NDEF_MB            0x80u
#define NDEF_ME            0x40u
#define NDEF_CF            0x20u
#define NDEF_SR            0x10u
#define NDEF_IL            0x08u
#define NDEF_TNF_MASK      0x07u
#define NDEF_TNF_EXTERNAL  0x04u

/* ── 帧打印 ── */

static void print_frame(const char *channel, const char *dir,
			const uint8_t *buf, size_t len)
{
	printk("[%s] %s (%u bytes):", channel, dir, (unsigned)len);
	for (size_t i = 0; i < len; i++) {
		if (i % 16 == 0) {
			printk("\n  %02x:", (unsigned)i);
		}
		printk(" %02x", buf[i]);
	}
	printk("\n");
}

/* ── 手动NDEF记录解析 ── */

static bool ndef_parse_ext_cmd(const uint8_t *ndef_msg, uint32_t ndef_msg_len,
			       uint8_t *cmd_out,
			       const uint8_t **payload_out,
			       uint32_t *payload_len_out)
{
	if (ndef_msg_len < 3) {
		return false;
	}

	uint8_t flags = ndef_msg[0];
	uint8_t tnf   = flags & NDEF_TNF_MASK;

	if (tnf != NDEF_TNF_EXTERNAL) {
		return false;
	}

	uint8_t type_len = ndef_msg[1];

	uint32_t payload_len;
	uint32_t header_len;

	if (flags & NDEF_SR) {
		payload_len = ndef_msg[2];
		header_len = 3;
	} else {
		if (ndef_msg_len < 6) {
			return false;
		}
		payload_len = ((uint32_t)ndef_msg[2] << 24) |
			      ((uint32_t)ndef_msg[3] << 16) |
			      ((uint32_t)ndef_msg[4] << 8) |
			      ((uint32_t)ndef_msg[5]);
		header_len = 6;
	}

	if (flags & NDEF_IL) {
		if (ndef_msg_len < header_len + 1) {
			return false;
		}
		uint8_t id_len = ndef_msg[header_len];
		header_len += 1 + id_len;
	}

	if (ndef_msg_len < header_len + type_len + payload_len) {
		return false;
	}

	const uint8_t *type = &ndef_msg[header_len];

	if (type_len != APP_CONFIG_CMD_TYPE_LEN) {
		return false;
	}
	if (memcmp(type, APP_CONFIG_CMD_TYPE, APP_CONFIG_CMD_TYPE_LEN) != 0) {
		return false;
	}

	if (payload_len < 1) {
		return false;
	}

	const uint8_t *payload = &ndef_msg[header_len + type_len];
	*cmd_out = payload[0];

	if (payload_out) {
		*payload_out = payload;
	}
	if (payload_len_out) {
		*payload_len_out = payload_len;
	}
	return true;
}

/* ── 手动NDEF消息编码 ── */

/**
 * @brief 将应答payload编码为NDEF消息（"ulpinternal:info" External Type）。
 * @param payload     应答payload（长度可变）
 * @param pay_len     payload 字节数
 * @param dst         目标缓冲区
 * @param dst_len     输入=缓冲区大小，输出=实际编码长度
 * @return 0=成功，负值=错误
 */
static int ndef_encode_response(const uint8_t *payload, uint32_t pay_len,
				uint8_t *dst, uint32_t *dst_len)
{
	uint32_t type_len = APP_CONFIG_INFO_TYPE_LEN;

	/* 记录头: flags(1) + type_len(1) + pay_len_SR(1) = 3 */
	uint32_t total = 3 + type_len + pay_len;

	if (*dst_len < total) {
		return -1;
	}

	uint8_t *p = dst;

	/* flags: MB=1, ME=1, SR=1, TNF=External */
	*p++ = NDEF_MB | NDEF_ME | NDEF_SR | NDEF_TNF_EXTERNAL;
	/* type length */
	*p++ = (uint8_t)type_len;
	/* payload length (SR mode, 1 byte) */
	*p++ = (uint8_t)pay_len;
	/* type */
	memcpy(p, APP_CONFIG_INFO_TYPE, type_len);
	p += type_len;
	/* payload */
	memcpy(p, payload, pay_len);
	p += pay_len;

	*dst_len = (uint32_t)(p - dst);
	return 0;
}

/* ── 公共接口 ── */

bool app_config_handle_ndef(uint8_t *ndef_msg_buf, size_t ndef_msg_buf_size)
{
	/* 获取NDEF消息（跳过2字节NLEN） */
	uint8_t *ndef_msg = nfc_t4t_ndef_file_msg_get(ndef_msg_buf);
	uint32_t ndef_msg_size = nfc_t4t_ndef_file_msg_size_get(ndef_msg_buf_size);

	/* 解析命令 */
	uint8_t cmd;
	const uint8_t *payload;
	uint32_t payload_len;
	if (!ndef_parse_ext_cmd(ndef_msg, ndef_msg_size, &cmd,
				&payload, &payload_len)) {
		return false;
	}

	print_frame("NFC", "RX cmd", payload, payload_len);

	/* ── 统一协议处理 ── */
	uint8_t resp[APP_PROTO_RESP_MAX];
	uint16_t resp_len = process_app_payload("NFC", payload,
						(uint16_t)payload_len,
						resp, sizeof(resp));
	if (resp_len == 0) {
		return false;
	}

	print_frame("NFC", "TX resp", resp, resp_len);

	/* 编码应答NDEF消息 */
	uint8_t *raw_msg = nfc_t4t_ndef_file_msg_get(ndef_msg_buf);
	uint32_t raw_msg_size = nfc_t4t_ndef_file_msg_size_get(ndef_msg_buf_size);

	int err = ndef_encode_response(resp, resp_len, raw_msg, &raw_msg_size);
	if (err) {
		printk("[NFC] encode error %d\n", err);
		return false;
	}

	/* 写入NLEN前缀 */
	err = nfc_t4t_ndef_file_encode(ndef_msg_buf, &raw_msg_size);
	if (err) {
		printk("[NFC] file encode error %d\n", err);
		return false;
	}

	return true;
}

uint16_t app_config_handle_ble(const uint8_t *data, uint16_t len, uint8_t *resp)
{
	if (len < 1) {
		return 0;
	}

	uint8_t cmd = data[0];

	/* ── OTA 命令：保留 BLE 专用逻辑，不进入 process_app_payload ── */

	/* OTA 数据包不打印帧（频繁，会刷屏） */
	if (cmd != APP_CONFIG_CMD_OTA_DATA) {
		print_frame("BLE", "RX cmd", data, len);
	}

	if (cmd == APP_CONFIG_CMD_OTA_START) {
		uint8_t auth_st = app_auth_check_write("BLE");
		if (auth_st != APP_CONFIG_STATUS_OK) {
			resp[0] = APP_CONFIG_CMD_OTA_START;
			resp[1] = auth_st;
			print_frame("BLE", "TX resp", resp, 2);
			return 2;
		}
		memset(&g_ota, 0, offsetof(struct ota_state, buf));
		if (len >= 5) {
			g_ota.total_size = ((uint32_t)data[1] << 24) |
					   ((uint32_t)data[2] << 16) |
					   ((uint32_t)data[3] << 8)  |
					   (uint32_t)data[4];
		}
		g_ota.active = true;
		printk("[BLE] OTA start: total=%u bytes\n", g_ota.total_size);
		resp[0] = APP_CONFIG_CMD_OTA_START;
		resp[1] = APP_CONFIG_STATUS_OK;
		print_frame("BLE", "TX resp", resp, 2);
		return 2;
	}

	if (cmd == APP_CONFIG_CMD_OTA_DATA) {
		uint8_t auth_st = app_auth_check_write("BLE");
		if (auth_st != APP_CONFIG_STATUS_OK) {
			resp[0] = APP_CONFIG_CMD_OTA_DATA;
			resp[1] = auth_st;
			print_frame("BLE", "TX resp", resp, 2);
			return 2;
		}
		if (!g_ota.active) {
			resp[0] = APP_CONFIG_CMD_OTA_DATA;
			resp[1] = APP_CONFIG_STATUS_OTA_STATE;
			printk("[BLE] OTA data without start\n");
			print_frame("BLE", "TX resp", resp, 2);
			return 2;
		}

		if (len >= 4) {
			uint16_t idx      = ((uint16_t)data[1] << 8) | data[2];
			uint16_t data_len = len - 3;
			uint32_t offset   = (uint32_t)idx * APP_CONFIG_OTA_PKT_DATA;

			if (offset + data_len <= APP_CONFIG_OTA_BUF_SIZE) {
				memcpy(&g_ota.buf[offset], &data[3], data_len);
				g_ota.bytes_received += data_len;
			} else {
				printk("[BLE] OTA buf full, drop idx=%u\n", idx);
			}
			g_ota.next_idx = idx + 1;
		}
		return 0;  /* 流式模式不应答 */
	}

	if (cmd == APP_CONFIG_CMD_OTA_END) {
		uint8_t auth_st = app_auth_check_write("BLE");
		if (auth_st != APP_CONFIG_STATUS_OK) {
			resp[0] = APP_CONFIG_CMD_OTA_END;
			resp[1] = auth_st;
			print_frame("BLE", "TX resp", resp, 2);
			return 2;
		}
		g_ota.active = false;
		g_ota.done   = true;
		printk("[BLE] OTA end: %u bytes in %u packets\n",
		       g_ota.bytes_received, g_ota.next_idx);
		resp[0] = APP_CONFIG_CMD_OTA_END;
		resp[1] = APP_CONFIG_STATUS_OK;
		print_frame("BLE", "TX resp", resp, 2);
		return 2;
	}

	/* ── CMD 0x01 / 0x02 / 0x03 / 0x04 统一协议处理 ── */
	uint8_t  internal_buf[APP_PROTO_RESP_MAX];
	uint16_t resp_len = process_app_payload("BLE", data, len,
						internal_buf, sizeof(internal_buf));
	if (resp_len > 0) {
		memcpy(resp, internal_buf, resp_len);
		print_frame("BLE", "TX resp", resp, resp_len);
	}
	return resp_len;
}
```

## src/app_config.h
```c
/*
 * Copyright (c) 2024
 *
 * SPDX-License-Identifier: LicenseRef-Nordic-5-Clause
 */

#ifndef APP_CONFIG_H__
#define APP_CONFIG_H__

#include <stdint.h>
#include <stddef.h>
#include <stdbool.h>

#ifdef __cplusplus
extern "C" {
#endif

/* V2.0 协议常量（含向后兼容别名） */
#include "app_protocol.h"

/** External Type 字符串 */
#define APP_CONFIG_CMD_TYPE      "ulpinternal:cmd"
#define APP_CONFIG_CMD_TYPE_LEN  15
#define APP_CONFIG_INFO_TYPE     "ulpinternal:info"
#define APP_CONFIG_INFO_TYPE_LEN 16

/** OTA 调试缓冲区（RAM，32KB）*/
#define APP_CONFIG_OTA_BUF_SIZE  (32 * 1024)
#define APP_CONFIG_OTA_PKT_DATA  492

struct app_config_ota_info {
	bool     active;
	bool     done;
	uint32_t total_size;
	uint16_t packets_received;
	uint32_t bytes_received;
};

void app_config_ota_get_info(struct app_config_ota_info *info);
const uint8_t *app_config_ota_get_buf(void);

/* 传感器数据更新接口 */
void app_config_set_battery(uint8_t level);
void app_config_set_temperature(int16_t temp);
void app_config_set_distance(uint16_t dist);
void app_config_set_position(uint8_t pos);
void app_config_set_mode(uint8_t mode);
void app_config_set_update_time(uint16_t interval);
void app_config_set_gnss_fix(uint8_t fix);
void app_config_set_latitude(int32_t lat);
void app_config_set_longitude(int32_t lng);
void app_config_set_altitude(int16_t alt);

/* 全局时间戳（APP CMD 0x01 附带） */
uint32_t app_config_get_unixtime(void);

/**
 * @brief 处理收到的NDEF消息，解析命令并更新为应答数据帧。
 *
 *        在 NFC_T4T_EVENT_NDEF_UPDATED 事件中调用。
 *        如果识别为有效的配置命令，则将 ndef_msg_buf 替换为应答NDEF消息，
 *        并更新T4T载荷。
 *
 * @param ndef_msg_buf     NDEF文件缓冲区（含NLEN前缀）
 * @param ndef_msg_buf_size 缓冲区总大小
 * @return true  已识别命令并更新应答
 * @return false 不是配置命令，调用者按原有逻辑处理
 */
bool app_config_handle_ndef(uint8_t *ndef_msg_buf, size_t ndef_msg_buf_size);

/**
 * @brief 处理BLE收到的裸命令。
 *
 *        命令格式: [CMD, ...params]
 *        应答写入 resp 缓冲区，返回实际字节数。
 *
 * @param data   BLE收到的原始bytes
 * @param len    数据长度
 * @param resp   输出缓冲区，须>=APP_PROTO_RESP_MAX(256)字节
 * @return 实际应答字节数，0 表示无需回复（如 OTA 数据包）
 */
uint16_t app_config_handle_ble(const uint8_t *data, uint16_t len, uint8_t *resp);

#ifdef __cplusplus
}
#endif

#endif /* APP_CONFIG_H__ */
```

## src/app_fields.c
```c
/*
 * Copyright (c) 2024
 *
 * SPDX-License-Identifier: LicenseRef-Nordic-5-Clause
 */

/**
 * @file app_fields.c
 * @brief V2.0 字段注册表实现。
 *
 * 管理所有 FIELD_ID 的存储、读写、校验。设备状态 RAM-only。
 * 网络/平台预留字段 0x30~0x36 不注册，返回 UNSUPPORTED。
 */

#include "app_fields.h"
#include "app_protocol.h"
#include <string.h>
#include <zephyr/sys/printk.h>

/* ═══════════════════════════════════════════════════════════════════════
 * 字段数据存储
 * ═══════════════════════════════════════════════════════════════════════ */

/* 设备基础信息（只读） */
static uint8_t  g_device_type     = DEVICE_TYPE_RL;       /* 0x02 */
static char     g_model[]         = "RL_TN100";           /* 0x03 */
static char     g_sn[]            = "123456";             /* 0x04 */
static uint8_t  g_fw_ver[3]       = {1, 0, 0};           /* 0x05 */
static uint8_t  g_hw_ver[3]       = {1, 0, 0};           /* 0x06 */
static uint8_t  g_protocol_ver    = PROTOCOL_VERSION_VALUE; /* 0x07 */

/* 传感器数据（只读） */
static uint8_t  g_battery         = 100;                  /* 0x10 */
static int16_t  g_temperature     = 250;                  /* 0x11, 25.0°C */
static uint16_t g_distance        = 15;                   /* 0x12, cm */
static uint8_t  g_position        = 0x00;                 /* 0x13 */

/* 可写配置字段 */
static uint8_t  g_mode            = 0x02;                 /* 0x20, 1=快递箱 2=垃圾桶 3=货架 */
static uint16_t g_update_interval = 0;                    /* 0x21, 分钟 */
static int32_t  g_install_lat     = 246087800;            /* 0x22, 24.60878°N */
static int32_t  g_install_lng     = 1180689300;           /* 0x22, 118.06893°E */

/* 衍生定位字段（写入 INSTALL_LOCATION 或外部更新后同步） */
static uint8_t  g_gnss_fix        = 0x01;                 /* 0x23 */
static int32_t  g_latitude        = 246087800;            /* 0x24 */
static int32_t  g_longitude       = 1180689300;           /* 0x25 */
static int16_t  g_altitude        = 15;                   /* 0x26, m */

/* ═══════════════════════════════════════════════════════════════════════
 * 设备状态机（RAM-only，重启回 FACTORY）
 * ═══════════════════════════════════════════════════════════════════════ */

static uint8_t g_device_state      = DEVICE_STATE_FACTORY;
static bool    g_factory_init_done = false;

/* 全局时间戳（APP CMD 0x01 附带） */
static uint32_t g_unixtime;

/* ═══════════════════════════════════════════════════════════════════════
 * 字段权限判断
 * ═══════════════════════════════════════════════════════════════════════ */

/** @brief 字段是否可读 */
static bool field_is_readable(uint8_t field_id)
{
	switch (field_id) {
	case FIELD_DEVICE_STATE:
	case FIELD_DEVICE_TYPE:
	case FIELD_MODEL:
	case FIELD_SN:
	case FIELD_FW_VER:
	case FIELD_HW_VER:
	case FIELD_PROTOCOL_VERSION:
	case FIELD_BATTERY:
	case FIELD_TEMPERATURE:
	case FIELD_DISTANCE:
	case FIELD_POSITION:
	case FIELD_MODE:
	case FIELD_UPDATE_INTERVAL:
	case FIELD_INSTALL_LOCATION:
	case FIELD_GNSS_FIX:
	case FIELD_LATITUDE:
	case FIELD_LONGITUDE:
	case FIELD_ALTITUDE:
		return true;
	default:
		return false; /* 0x30~0x36 等预留字段 */
	}
}

/** @brief 字段是否可写 */
static bool field_is_writable(uint8_t field_id)
{
	switch (field_id) {
	case FIELD_MODE:
	case FIELD_UPDATE_INTERVAL:
	case FIELD_INSTALL_LOCATION:
		return true;
	default:
		return false;
	}
}

/* ═══════════════════════════════════════════════════════════════════════
 * 字段长度查询
 * ═══════════════════════════════════════════════════════════════════════ */

/** @brief 获取字段的固定值长度，0 表示变长 */
static uint8_t field_value_len(uint8_t field_id)
{
	switch (field_id) {
	case FIELD_DEVICE_STATE:      return 1;
	case FIELD_DEVICE_TYPE:       return 1;
	case FIELD_MODEL:             return 0; /* 变长 */
	case FIELD_SN:                return 0; /* 变长 */
	case FIELD_FW_VER:            return 3;
	case FIELD_HW_VER:            return 3;
	case FIELD_PROTOCOL_VERSION:  return 1;
	case FIELD_BATTERY:           return 1;
	case FIELD_TEMPERATURE:       return 2;
	case FIELD_DISTANCE:          return 2;
	case FIELD_POSITION:          return 1;
	case FIELD_MODE:              return 1;
	case FIELD_UPDATE_INTERVAL:   return 2;
	case FIELD_INSTALL_LOCATION:  return 8;
	case FIELD_GNSS_FIX:          return 1;
	case FIELD_LATITUDE:          return 4;
	case FIELD_LONGITUDE:         return 4;
	case FIELD_ALTITUDE:          return 2;
	default:                      return 0;
	}
}

/* ═══════════════════════════════════════════════════════════════════════
 * 大端序编解码辅助
 * ═══════════════════════════════════════════════════════════════════════ */

static void put_u16_be(uint8_t *buf, uint16_t v)
{
	buf[0] = (uint8_t)(v >> 8);
	buf[1] = (uint8_t)(v);
}

static void put_u32_be(uint8_t *buf, uint32_t v)
{
	buf[0] = (uint8_t)(v >> 24);
	buf[1] = (uint8_t)(v >> 16);
	buf[2] = (uint8_t)(v >> 8);
	buf[3] = (uint8_t)(v);
}

static uint16_t get_u16_be(const uint8_t *buf)
{
	return ((uint16_t)buf[0] << 8) | buf[1];
}

static uint32_t get_u32_be(const uint8_t *buf)
{
	return ((uint32_t)buf[0] << 24) |
	       ((uint32_t)buf[1] << 16) |
	       ((uint32_t)buf[2] << 8)  |
	       (uint32_t)buf[3];
}

/* ═══════════════════════════════════════════════════════════════════════
 * 传感器值外部更新接口（供 app_config.c setter 函数调用）
 * ═══════════════════════════════════════════════════════════════════════ */

void app_field_set_battery(uint8_t level)     { g_battery = level; }
void app_field_set_temperature(int16_t temp)   { g_temperature = temp; }
void app_field_set_distance(uint16_t dist)     { g_distance = dist; }
void app_field_set_position(uint8_t pos)       { g_position = pos; }
void app_field_set_gnss_fix(uint8_t fix)       { g_gnss_fix = fix; }
void app_field_set_latitude(int32_t lat)       { g_latitude = lat; }
void app_field_set_longitude(int32_t lng)      { g_longitude = lng; }
void app_field_set_altitude(int16_t alt)       { g_altitude = alt; }

/* ═══════════════════════════════════════════════════════════════════════
 * 公共 API
 * ═══════════════════════════════════════════════════════════════════════ */

void app_fields_init(void)
{
	/* 设备状态 */
	g_device_state      = DEVICE_STATE_FACTORY;
	g_factory_init_done = false;

	/* 可写配置字段恢复默认值 */
	g_mode            = 0x02;
	g_update_interval = 0;
	g_install_lat     = 246087800;
	g_install_lng     = 1180689300;

	/* 定位字段恢复默认 */
	g_gnss_fix  = 0x01;
	g_latitude  = 246087800;
	g_longitude = 1180689300;
	g_altitude  = 15;

	printk("[FIELDS] init OK, device_state=FACTORY, config defaults restored\n");
}

uint8_t app_field_get(uint8_t field_id, uint8_t *buf, uint8_t buf_max)
{
	if (!field_is_readable(field_id)) {
		return 0;
	}

	switch (field_id) {
	case FIELD_DEVICE_STATE:
		if (buf_max < 1) return 0;
		buf[0] = g_device_state;
		return 1;

	case FIELD_DEVICE_TYPE:
		if (buf_max < 1) return 0;
		buf[0] = g_device_type;
		return 1;

	case FIELD_MODEL: {
		uint8_t len = (uint8_t)strlen(g_model);
		if (len > buf_max) len = buf_max;
		memcpy(buf, g_model, len);
		return len;
	}
	case FIELD_SN: {
		uint8_t len = (uint8_t)strlen(g_sn);
		if (len > buf_max) len = buf_max;
		memcpy(buf, g_sn, len);
		return len;
	}
	case FIELD_FW_VER:
		if (buf_max < 3) return 0;
		memcpy(buf, g_fw_ver, 3);
		return 3;

	case FIELD_HW_VER:
		if (buf_max < 3) return 0;
		memcpy(buf, g_hw_ver, 3);
		return 3;

	case FIELD_PROTOCOL_VERSION:
		if (buf_max < 1) return 0;
		buf[0] = g_protocol_ver;
		return 1;

	case FIELD_BATTERY:
		if (buf_max < 1) return 0;
		buf[0] = g_battery;
		return 1;

	case FIELD_TEMPERATURE:
		if (buf_max < 2) return 0;
		put_u16_be(buf, (uint16_t)g_temperature);
		return 2;

	case FIELD_DISTANCE:
		if (buf_max < 2) return 0;
		put_u16_be(buf, g_distance);
		return 2;

	case FIELD_POSITION:
		if (buf_max < 1) return 0;
		buf[0] = g_position;
		return 1;

	case FIELD_MODE:
		if (buf_max < 1) return 0;
		buf[0] = g_mode;
		return 1;

	case FIELD_UPDATE_INTERVAL:
		if (buf_max < 2) return 0;
		put_u16_be(buf, g_update_interval);
		return 2;

	case FIELD_INSTALL_LOCATION:
		if (buf_max < 8) return 0;
		put_u32_be(buf,     (uint32_t)g_install_lat);
		put_u32_be(buf + 4, (uint32_t)g_install_lng);
		return 8;

	case FIELD_GNSS_FIX:
		if (buf_max < 1) return 0;
		buf[0] = g_gnss_fix;
		return 1;

	case FIELD_LATITUDE:
		if (buf_max < 4) return 0;
		put_u32_be(buf, (uint32_t)g_latitude);
		return 4;

	case FIELD_LONGITUDE:
		if (buf_max < 4) return 0;
		put_u32_be(buf, (uint32_t)g_longitude);
		return 4;

	case FIELD_ALTITUDE:
		if (buf_max < 2) return 0;
		put_u16_be(buf, (uint16_t)g_altitude);
		return 2;

	default:
		return 0;
	}
}

uint8_t app_field_validate(uint8_t field_id, const uint8_t *value, uint8_t len)
{
	/* 检查字段是否存在 */
	if (!field_is_readable(field_id)) {
		return APP_PROTO_STATUS_UNSUPPORTED;
	}

	/* 检查是否可写 */
	if (!field_is_writable(field_id)) {
		return APP_PROTO_STATUS_UNSUPPORTED;
	}

	/* 检查长度 */
	uint8_t expected_len = field_value_len(field_id);
	if (expected_len > 0 && len != expected_len) {
		return APP_PROTO_STATUS_PARAM_LEN;
	}

	/* 值域校验 */
	switch (field_id) {
	case FIELD_MODE:
		if (value[0] < 0x01 || value[0] > 0x03) {
			printk("[FIELDS] invalid mode 0x%02x\n", value[0]);
			return APP_PROTO_STATUS_PARAM_VALUE;
		}
		break;

	case FIELD_UPDATE_INTERVAL:
		/* 0~65535 均合法，仅检查长度 */
		break;

	case FIELD_INSTALL_LOCATION: {
		int32_t lat = (int32_t)get_u32_be(value);
		int32_t lng = (int32_t)get_u32_be(value + 4);

		if (lat < -900000000 || lat > 900000000 ||
		    lng < -1800000000 || lng > 1800000000) {
			printk("[FIELDS] invalid location: lat=%d, lng=%d\n", lat, lng);
			return APP_PROTO_STATUS_PARAM_VALUE;
		}
		break;
	}
	default:
		break;
	}

	return APP_PROTO_STATUS_OK;
}

void app_field_set(uint8_t field_id, const uint8_t *value, uint8_t len)
{
	switch (field_id) {
	case FIELD_MODE:
		g_mode = value[0];
		printk("[FIELDS] mode set to 0x%02x\n", g_mode);
		break;

	case FIELD_UPDATE_INTERVAL:
		g_update_interval = get_u16_be(value);
		printk("[FIELDS] interval set to %u min\n", g_update_interval);
		break;

	case FIELD_INSTALL_LOCATION: {
		g_install_lat = (int32_t)get_u32_be(value);
		g_install_lng = (int32_t)get_u32_be(value + 4);
		/* 写入安装位置后同步定位字段 */
		g_gnss_fix  = 0x01;
		g_latitude  = g_install_lat;
		g_longitude = g_install_lng;
		g_altitude  = 0;
		printk("[FIELDS] install_pos: lat=%d, lng=%d\n",
		       g_install_lat, g_install_lng);
		break;
	}
	default:
		break;
	}
}

uint8_t app_field_get_device_state(void)
{
	return g_device_state;
}

void app_field_set_device_state(uint8_t state)
{
	g_device_state = state;
	printk("[FIELDS] device_state -> 0x%02x\n", g_device_state);
}

bool app_field_is_factory_init_done(void)
{
	return g_factory_init_done;
}

void app_field_mark_factory_init_done(void)
{
	g_factory_init_done = true;
	if (g_device_state == DEVICE_STATE_FACTORY) {
		g_device_state = DEVICE_STATE_POWER_ON;
		printk("[FIELDS] factory init done, state -> POWER_ON\n");
	}
}

void app_field_set_unixtime(uint32_t ts)
{
	g_unixtime = ts;
}

uint32_t app_field_get_unixtime(void)
{
	return g_unixtime;
}
```

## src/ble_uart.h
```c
/*
 * Copyright (c) 2024 Nordic Semiconductor ASA
 *
 * SPDX-License-Identifier: LicenseRef-Nordic-5-Clause
 */

#ifndef BLE_UART_H__
#define BLE_UART_H__

#ifdef __cplusplus
extern "C" {
#endif

/**
 * @brief Initialize BLE UART service (NUS).
 *
 *        Initializes UART, Bluetooth stack, NUS service, and starts
 *        advertising. A dedicated thread forwards UART RX data to BLE.
 *
 * @return 0 on success, negative on error.
 */
int ble_uart_init(void);

#ifdef __cplusplus
}
#endif

#endif /* BLE_UART_H__ */
```
